# STM32U083 register map
File version: 1.0
CPU: CM0+ r0p1, little endian, MPU, no FPU, 4 interrupt priority bits
Registers are 32-bit, read-write, reset 0x0 unless marked. A register's access mark holds for its fields unless they carry their own. Offsets are from the block's base; [hi:lo] are bit positions; lines under a group give offsets from that group; {n}, {i} and the like mark numbered series.

## SYSCFG — SYSCFG register block
Base 0x40010000
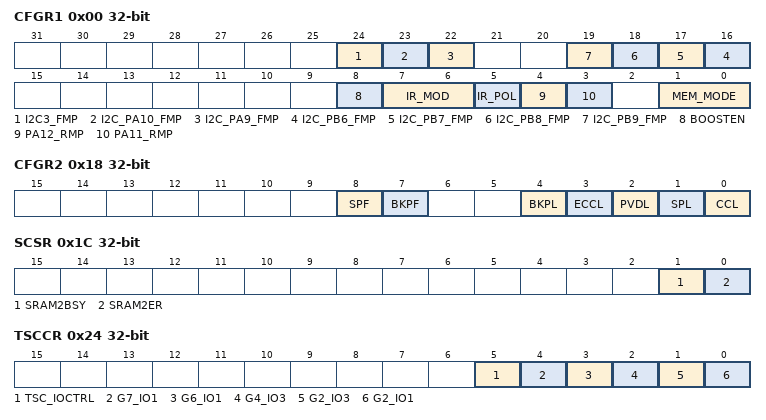
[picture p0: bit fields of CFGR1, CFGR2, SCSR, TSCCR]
0x00 CFGR1 (reset mask 0xFFFFFFF0) — SYSCFG configuration register 1
  [24] I2C3_FMP — Fast Mode Plus (FM+) enable for I2C3 This bit is set and cleared by software. It enables I<sup>2</sup>C FM+ driving capability on I/O ports configured as I2C3 through GPIOx_AFR registers. With this bit in disable state, the I<sup>2</sup>C FM+ driving capability on I/O ports configured as I2C3 can be enabled through their corresponding I2Cx_FMP bit. When I<sup>2</sup>C FM+ is enabled, the speed control is ignored. Note: This control bit is kept for legacy reasons. It is recommended to use the FMP bit of the I2Cx_CR1 register instead.
  [23] I2C_PA10_FMP — Fast Mode Plus (FM+) enable for PA10 This bit is set and cleared by software. It enables I<sup>2</sup>C FM+ driving capability on PA10 I/O port. With this bit in disable state, the I<sup>2</sup>C FM+ driving capability on this I/O port can be enabled through one of I2Cx_FMP bits. When I<sup>2</sup>C FM+ is enabled, the speed control is ignored. Note: This control bit is kept for legacy reasons. It is recommended to use the FMP bit of the I2Cx_CR1 register instead.
  [22] I2C_PA9_FMP — Fast Mode Plus (FM+) enable for PA9 This bit is set and cleared by software. It enables I<sup>2</sup>C FM+ driving capability on PA9 I/O port. With this bit in disable state, the I<sup>2</sup>C FM+ driving capability on this I/O port can be enabled through one of I2Cx_FMP bits. When I<sup>2</sup>C FM+ is enabled, the speed control is ignored. Note: This control bit is kept for legacy reasons. It is recommended to use the FMP bit of the I2Cx_CR1 register instead.
  [n+10] I2C_PB{n}_FMP (n=6..9) — Fast Mode Plus (FM+) enable for PB{n} This bit is set and cleared by software. It enables I<sup>2</sup>C FM+ driving capability on PB{n} I/O port. With this bit in disable state, the I<sup>2</sup>C FM+ driving capability on this I/O port can be enabled through one of I2Cx_FMP bits. When I<sup>2</sup>C FM+ is enabled, the speed control is ignored. Note: This control bit is kept for legacy reasons. It is recommended to use the FMP bit of the I2Cx_CR1 register instead.
  [8] BOOSTEN — I/O analog switch voltage booster enable This bit selects the way of supplying I/O analog switches: When using the analog inputs , setting to 0 is recommended for high V<sub>DD</sub>, setting to 1 for low V<sub>DD</sub> (less than 2.4 V).
  [7:6] IR_MOD — IR Modulation Envelope signal selection This bitfield selects the signal for IR modulation envelope:
  [5] IR_POL — IR output polarity selection
  [4] PA12_RMP — PA12 pin remapping This bit is set and cleared by software. When set, it remaps the PA12 pin to operate as PA10 GPIO port, instead as PA12 GPIO port.
  [3] PA11_RMP — PA11 pin remapping This bit is set and cleared by software. When set, it remaps the PA11 pin to operate as PA9 GPIO port, instead as PA11 GPIO port.
  [1:0] MEM_MODE — Memory mapping selection bits These bits are set and cleared by software. They control the memory internal mapping at address 0x000010000. After reset these bits take on the value selected by the actual boot mode configuration. Refer to Section12.5: Boot configuration for more details. X0: Main flash memory mapped at 0x000010000
0x18 CFGR2 — SYSCFG configuration register 2
  [8] SPF — SRAM1 parity error flag This bit is set by hardware when an SRAM1 parity error is detected. It is cleared by software by writing 1.
  [7] BKPF — Backup SRAM2 parity error flag This bit is set by hardware when an SRAM2 parity error is detected. It is cleared by software by writing 1.
  [4] BKPL — Backup SRAM2 parity lock This bit is set by software and cleared by a system reset. It can be used to enable and lock the SRAM2 parity error signal connection to TIM1/15/16 Break input.
  [3] ECCL — ECC error lock bit This bit is set by software and cleared by a system reset. It can be used to enable and lock the flash ECC 2-bit error detection signal connection to TIM1/15/16 Break input.
  [2] PVDL — PVD lock enable bit This bit is set by software and cleared by a system reset. It can be used to enable and lock the PVD connection to TIM1/15/16 Break input, as well as the PVDE and PLS[2:0] in the PWR_CR register.
  [1] SPL — SRAM1 parity lock bit This bit is set by software and cleared by a system reset. It can be used to enable and lock the SRAM1 parity error signal connection to TIM1/15/16 Break input.
  [0] CCL — Cortex<Superscript>1<Default 1 Font>-M0+ LOCKUP bit enable bit This bit is set by software and cleared by a system reset. It can be use to enable and lock the connection of Cortex<Superscript>1<Default 1 Font>-M0+ LOCKUP (Hardfault) output to TIM1/15/16 Break input.
0x1C SCSR access per field — SYSCFG SRAM2 control and status register
  [1] SRAM2BSY ro — SRAM2 busy by erase operation
  [0] SRAM2ER rw — SRAM2 erase Setting this bit starts a hardware SRAM2 erase operation. This bit is automatically cleared at the end of the SRAM2 erase operation. Note: This bit is write-protected: setting this bit is possible only after the correct key sequence is written in the SYSCFG_SKR register.
0x20 SKR wo — SYSCFG SRAM2 key register
  [7:0] KEY — SRAM2 write protection key for software erase The following steps are required to unlock the write protection of the SRAM2ER bit in the SYSCFG_CFGR2 register: Write 0xCA into KEY[7:0] Write 0x53 into KEY[7:0] Writing a wrong key reactivates the write protection.
0x24 TSCCR — SYSCFG TSC comparator register
  [5] TSC_IOCTRL — I/O control in comparator mode The I/O control in comparator mode can be overwritten by hardware.
  [4] G7_IO1 — Comparator mode for group 7 on I/O 1
  [3] G6_IO1 — Comparator mode for group 6 on I/O 1
  [2] G4_IO3 — Comparator mode for group 4 on I/O 3
  [1] G2_IO3 — Comparator mode for group 2 on I/O 3
  [0] G2_IO1 — Comparator mode for group 2 on I/O 1
0x80 ITLINE0 ro — SYSCFG interrupt line 0 status register
  [0] WWDG — Window watchdog interrupt pending flag
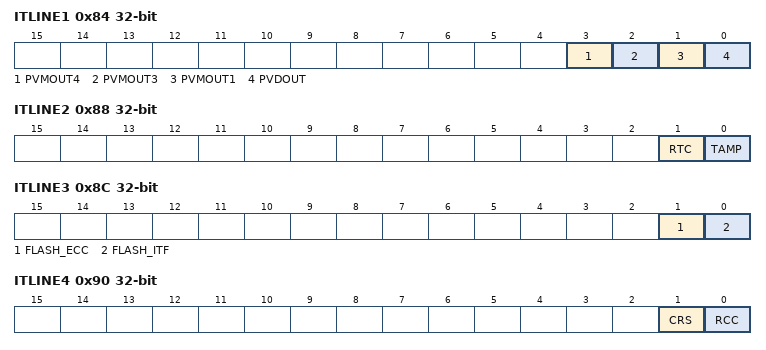
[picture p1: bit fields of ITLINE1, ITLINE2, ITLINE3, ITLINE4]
0x84 ITLINE1 ro — SYSCFG interrupt line 1 status register
  [3] PVMOUT4 — DAC supply monitoring interrupt request pending (EXTI line 21)
  [2] PVMOUT3 — ADC supply monitoring interrupt request pending (EXTI line 20)
  [1] PVMOUT1 — V<sub>DDUSB</sub> supply monitoring interrupt request pending (EXTI line 19)
  [0] PVDOUT — PVD supply monitoring interrupt request pending (EXTI line 16).
0x88 ITLINE2 ro — SYSCFG interrupt line 2 status register
  [1] RTC — RTC interrupt request pending (EXTI line 19)
  [0] TAMP — Tamper interrupt request pending (EXTI line 21)
0x8C ITLINE3 ro — SYSCFG interrupt line 3 status register
  [1] FLASH_ECC — Flash interface ECC interrupt request pending
  [0] FLASH_ITF — Flash interface interrupt request pending
0x90 ITLINE4 ro — SYSCFG interrupt line 4 status register
  [1] CRS — CRS interrupt request pending
  [0] RCC — Reset and clock control interrupt request pending
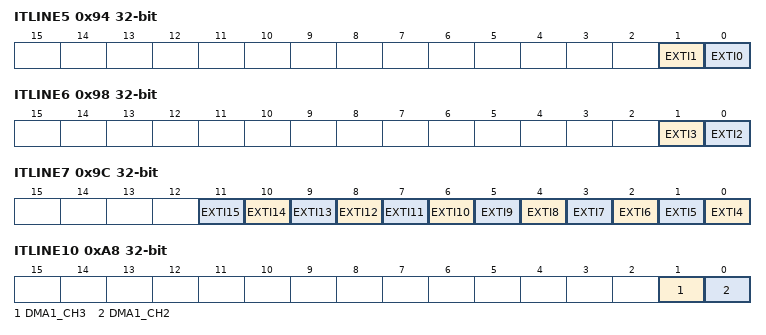
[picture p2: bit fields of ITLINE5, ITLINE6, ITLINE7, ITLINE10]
0x94 ITLINE5 ro — SYSCFG interrupt line 5 status register
  [1] EXTI1 — EXTI line 1 interrupt request pending
  [0] EXTI0 — EXTI line 0 interrupt request pending
0x98 ITLINE6 ro — SYSCFG interrupt line 6 status register
  [1] EXTI3 — EXTI line 3 interrupt request pending
  [0] EXTI2 — EXTI line 2 interrupt request pending
0x9C ITLINE7 ro — SYSCFG interrupt line 7 status register
  [n-4] EXTI{n} (n=4..15) — EXTI line {n} interrupt request pending
0xA0 ITLINE8 ro — SYSCFG interrupt line 8 status register
  [0] USB — USB interrupt request pending
0xA4 ITLINE9 ro — SYSCFG interrupt line 9 status register
  [0] DMA1_CH1 — DMA1 channel 1 interrupt request pending
0xA8 ITLINE10 ro — SYSCFG interrupt line 10 status register
  [1] DMA1_CH3 — DMA1 channel 3 interrupt request pending
  [0] DMA1_CH2 — DMA1 channel 2 interrupt request pending
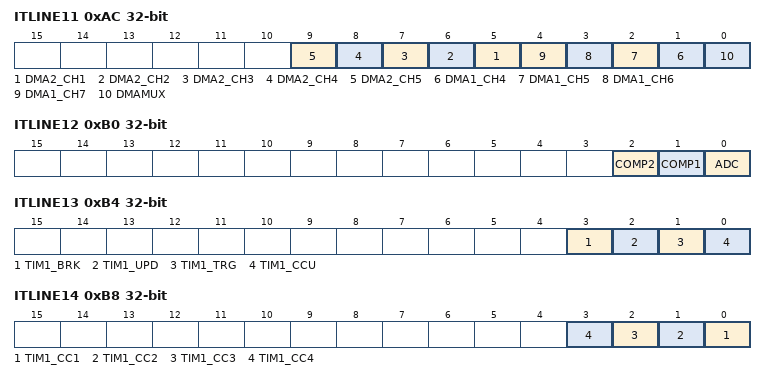
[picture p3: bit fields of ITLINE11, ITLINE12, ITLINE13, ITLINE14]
0xAC ITLINE11 ro — SYSCFG interrupt line 11 status register
  [n+4] DMA2_CH{n} (n=1..5) — DMA2 channel {n} interrupt request pending
  [n-3] DMA1_CH{n} (n=4..7) — DMA1 channel {n} interrupt request pending
  [0] DMAMUX — DMAMUX interrupt request pending
0xB0 ITLINE12 ro — SYSCFG interrupt line 12 status register
  [2] COMP2 — Comparator 2 interrupt request pending (EXTI line 18)
  [1] COMP1 — Comparator 1 interrupt request pending (EXTI line 17)
  [0] ADC — ADC interrupt request pending
0xB4 ITLINE13 ro — SYSCFG interrupt line 13 status register
  [3] TIM1_BRK — Timer 1 break interrupt request pending
  [2] TIM1_UPD — Timer 1 update interrupt request pending
  [1] TIM1_TRG — Timer 1 trigger interrupt request pending
  [0] TIM1_CCU — Timer 1 commutation interrupt request pending
0xB8 ITLINE14 ro — SYSCFG interrupt line 14 status register
  [n-1] TIM1_CC{n} (n=1..4) — Timer 1 capture compare {n} interrupt request pending
0xBC ITLINE15 ro — SYSCFG interrupt line 15 status register
  [0] TIM2 — Timer 2 interrupt request pending
0xC0 ITLINE16 ro — SYSCFG interrupt line 16 status register
  [0] TIM3 — Timer 3 interrupt request pending
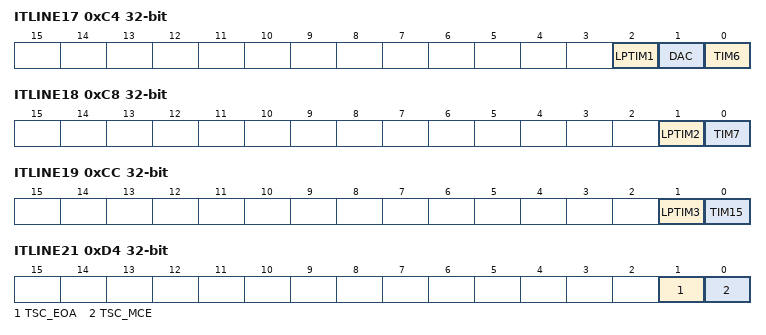
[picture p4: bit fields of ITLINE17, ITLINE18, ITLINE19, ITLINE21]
0xC4 ITLINE17 ro — SYSCFG interrupt line 17 status register
  [2] LPTIM1 — Low-power timer 1 interrupt request pending (EXTI line 29)
  [1] DAC — DAC underrun interrupt request pending
  [0] TIM6 — Timer 6 interrupt request pending
0xC8 ITLINE18 ro — SYSCFG interrupt line 18 status register
  [1] LPTIM2 — Low-power timer 2 interrupt request pending (EXTI line 30)
  [0] TIM7 — Timer 7 interrupt request pending
0xCC ITLINE19 ro — SYSCFG interrupt line 19 status register
  [1] LPTIM3 — Low-power timer 3 interrupt request pending
  [0] TIM15 — Timer 15 interrupt request pending
0xD0 ITLINE20 ro — SYSCFG interrupt line 20 status register
  [0] TIM16 — Timer 16 interrupt request pending
0xD4 ITLINE21 ro — SYSCFG interrupt line 21 status register
  [1] TSC_EOA — TSC end of acquisition interrupt request pending
  [0] TSC_MCE — TSC max count error interrupt request pending
0xD8 ITLINE22 ro — SYSCFG interrupt line 22 status register
  [0] LCD — LCD interrupt request pending
0xDC ITLINE23 ro — SYSCFG interrupt line 23 status register
  [0] I2C1 — I2C1 interrupt request pending (EXTI line 33)
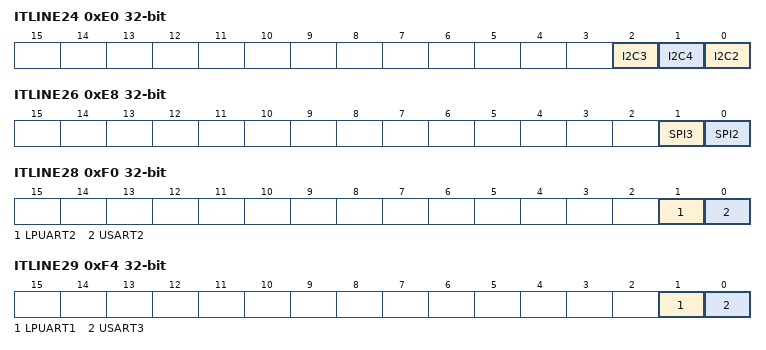
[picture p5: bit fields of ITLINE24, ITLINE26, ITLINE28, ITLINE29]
0xE0 ITLINE24 ro — SYSCFG interrupt line 24 status register
  [2] I2C3 — I2C3 interrupt request pending (EXTI line 23)
  [1] I2C4 — I2C4 interrupt request pending
  [0] I2C2 — I2C2 interrupt request pending
0xE4 ITLINE25 ro — SYSCFG interrupt line 25 status register
  [0] SPI1 — SPI1 interrupt request pending
0xE8 ITLINE26 ro — SYSCFG interrupt line 26 status register
  [1] SPI3 — SPI3 interrupt request pending
  [0] SPI2 — SPI2 interrupt request pending
0xEC ITLINE27 ro — SYSCFG interrupt line 27 status register
  [0] USART1 — USART1 interrupt request pending, combined with EXTI line 25
0xF0 ITLINE28 ro — SYSCFG interrupt line 28 status register
  [1] LPUART2 — LPUART2 interrupt request pending (EXTI line 31)
  [0] USART2 — USART2 interrupt request pending (EXTI line 35)
0xF4 ITLINE29 ro — SYSCFG interrupt line 29 status register
  [1] LPUART1 — LPUART1 interrupt request pending (EXTI line 30)
  [0] USART3 — USART3 interrupt request pending
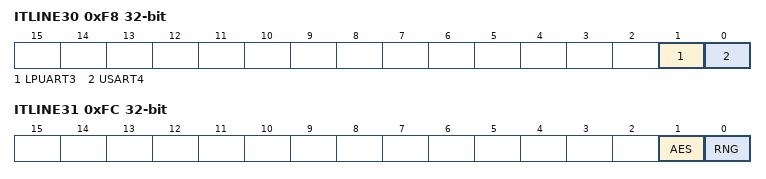
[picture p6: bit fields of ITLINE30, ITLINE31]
0xF8 ITLINE30 ro — SYSCFG interrupt line 30 status register
  [1] LPUART3 — LPUART3 interrupt request pending (EXTI line 32)
  [0] USART4 — USART4 interrupt request pending
0xFC ITLINE31 ro — SYSCFG interrupt line 31 status register
  [1] AES — AES interrupt request pending
  [0] RNG — RNG interrupt request pending
